# PY32F032xx register map
Vendor: Puya; Series: PY32F0; File version: 1.0.0
CPU: CM0+ r0p1, little endian, no MPU, no FPU, 4 interrupt priority bits
Registers are 32-bit, read-write, reset 0x0 unless marked. A register's access mark holds for its fields unless they carry their own. Offsets are from the block's base; [hi:lo] are bit positions; {n}, {i} and the like mark numbered series; 'fields as' and 'values as' point back to an identical list.

## COMP
Base 0x40010200
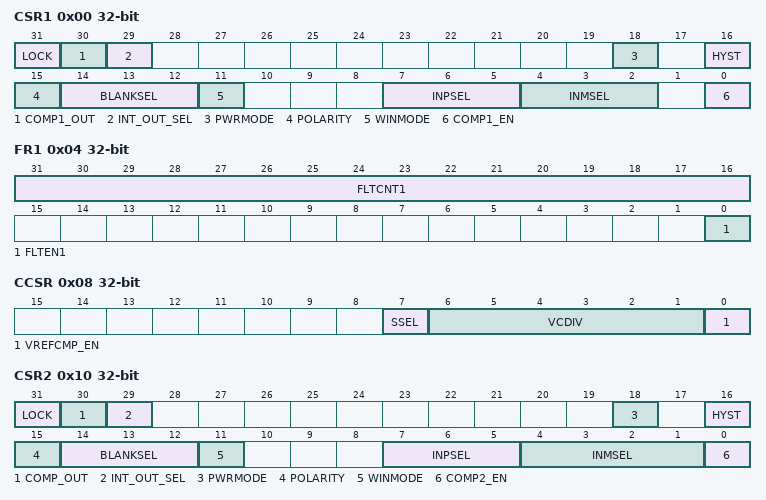
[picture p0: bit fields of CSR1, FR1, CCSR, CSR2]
0x00 CSR1
  [31] LOCK — COMP1_CSR registerlock
  [30] COMP1_OUT ro — COMP1 output status
  [29] INT_OUT_SEL — COMP1 output to TIM/EXTI selection
  [18] PWRMODE — COMP1 power mode selection
  [16] HYST — COMP1 hysteresis function enable control
  [15] POLARITY — COMP1 output polarity selection
  [14:12] BLANKSEL — Comparator 1 blanking signal selection
  [11] WINMODE — COMP1 window mode enable
  [7:5] INPSEL — COMP1 positive input select
  [4:2] INMSEL — COMP1 negative input select
  [0] COMP1_EN — COMP1 enable bit
0x04 FR1
  [31:16] FLTCNT1 — Comparator 1 sampling filter counter
  [0] FLTEN1 — Comparator 1 digital filter configuration
0x08 CCSR
  [7] SSEL
  [6:1] VCDIV
    1=0; 2=1; 4=2; 8=3; 16=4; 32=5
  [0] VREFCMP_EN — VREFCMP voltage divider enable signal
0x10 CSR2
  [31] LOCK — COMP2_CSR register lock
  [30] COMP_OUT ro — COMP2 output status
  [29] INT_OUT_SEL — COMP2 output to TIM/EXTI selection
  [18] PWRMODE — COMP2 power mode selection
  [16] HYST — COMP1 hysteresis function enable control
  [15] POLARITY — COMP2 output polarity selection
  [14:12] BLANKSEL — Comparator 2 blanking signal selection
  [11] WINMODE
  [7:5] INPSEL — COMP2 positive input select
  [4:1] INMSEL — COMP2 negative input select
  [0] COMP2_EN — COMP2 enable bit
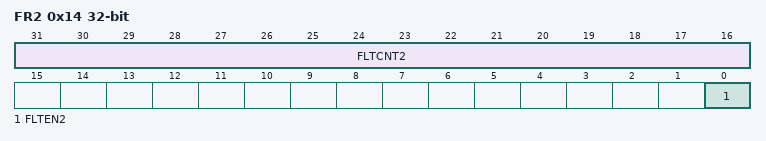
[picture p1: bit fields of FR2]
0x14 FR2
  [31:16] FLTCNT2 — Comparator 2 sampling filter counter
  [0] FLTEN2 — Comparator 2 digital filtering configuration

## CRC — CRC calculation unit
Base 0x40023000
0x00 DR — Data register
0x04 IDR — Independent Data register
  [7:0] IDR
0x08 CR wo — Control register
  [0] RESET

## DBGMCU — Debug support
Base 0x40015800
0x00 DBG_IDCODE
  [31:0] DBG_ID ro
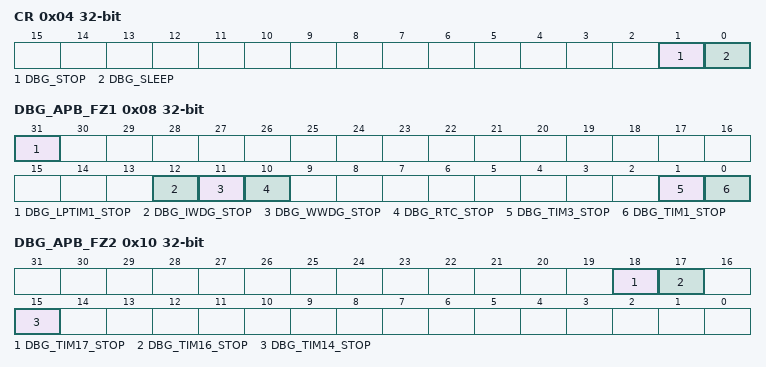
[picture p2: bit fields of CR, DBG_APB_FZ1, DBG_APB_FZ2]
0x04 CR — Debug MCU Configuration Register
  [1] DBG_STOP, [0] DBG_SLEEP
0x08 DBG_APB_FZ1
  [31] DBG_LPTIM1_STOP, [12] DBG_IWDG_STOP, [11] DBG_WWDG_STOP, [10] DBG_RTC_STOP, [1] DBG_TIM3_STOP, [0] DBG_TIM1_STOP
0x10 DBG_APB_FZ2
  [18] DBG_TIM17_STOP, [17] DBG_TIM16_STOP, [15] DBG_TIM14_STOP

## DMA — Direct memory access
Base 0x40020000
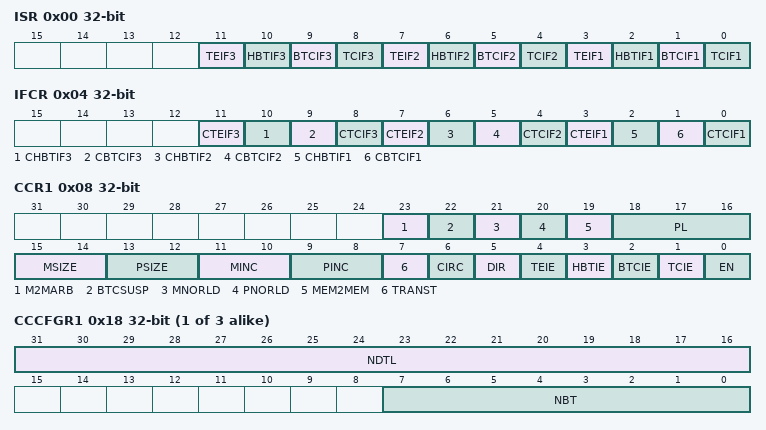
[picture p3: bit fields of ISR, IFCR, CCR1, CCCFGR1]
0x00 ISR — DMA interrupt status register(DMA_ISR)
  [11] TEIF3 ro — Transfer Error Flag for Channel 3
  [10] HBTIF3 ro — Half Block Transfer Complete Flag for Channel 3
  [9] BTCIF3 ro — Block Transfer Complete Flag for Channel 3
  [8] TCIF3 ro — Transfer Complete Flag for Channel 3
  [7] TEIF2 ro — Transfer Error Flag for Channel 2
  [6] HBTIF2 ro — Half Block Transfer Complete Flag for Channel 2
  [5] BTCIF2 ro — Block Transfer Complete Flag for Channel 2
  [4] TCIF2 ro — Transfer Complete Flag for Channel 2
  [3] TEIF1 ro — Transfer Error Flag for Channel 1
  [2] HBTIF1 ro — Half Block Transfer Complete Flag for Channel 1
  [1] BTCIF1 ro — Block Transfer Complete Flag for Channel 1
  [0] TCIF1 ro — Transfer Complete Flag for Channel 1
0x04 IFCR — DMA interrupt flag clear register(DMA_IFCR)
  [11] CTEIF3 — Transfer Error Flag Clear for Channel 3
  [10] CHBTIF3 — Half Block Transfer Complete Flag Clear for Channel 3
  [9] CBTCIF3 — Block Transfer Complete Flag Clear for Channel 3
  [8] CTCIF3 — Transfer Complete Flag Clear for Channel 3
  [7] CTEIF2 — Transfer Error Flag Clear for Channel 2
  [6] CHBTIF2 — Half Block Transfer Complete Flag Clear for Channel 2
  [5] CBTCIF2 — Block Transfer Complete Flag Clear for Channel 2
  [4] CTCIF2 — Transfer Complete Flag Clear for Channel 2
  [3] CTEIF1 — Transfer Error Flag Clear for Channel 1
  [2] CHBTIF1 — Half Block Transfer Complete Flag Clear for Channel 1
  [1] CBTCIF1 — Block Transfer Complete Flag Clear for Channel 1
  [0] CTCIF1 — Transfer Complete Flag Clear for Channel 1
0x08 CCR1 — DMA channel configuration register(DMA_CCR)
  [23] M2MARB — Memory-to-memory Mode Arbitration
  [22] BTCSUSP — Suspend in Block Transfer Complete Interrupt
  [21] MNORLD — Memory No Reload
  [20] PNORLD — Peripheral No Reload
  [19] MEM2MEM — Memory-to-memory Mode
  [18:16] PL — Priority Level
  [15:14] MSIZE — Memory Size
  [13:12] PSIZE — Peripheral Size
  [11:10] MINC — Memory Increment Mode
  [9:8] PINC — Peripheral Increment Mode
  [7] TRANST — Transfer Type
  [6] CIRC — Circular Mode
  [5] DIR — Data Transfer Direction
  [4] TEIE — Transfer Error Interrupt Enable
  [3] HBTIE — Half Block Transfer Complete Interrupt Enable
  [2] BTCIE — Block Transfer Complete Interrupt Enable
  [1] TCIE — Transfer Complete Interrupt Enable
  [0] EN — Channel Enable
0x0C CNDTR1 — DMA channel 1 number of dataregister
  [15:0] NDT — Number of Data to Transfer
0x10 CPAR1 — DMA channel 1 peripheral addressregister
  [31:0] PA — Peripheral Address
{0x0+0x14*i} CMAR{i} (i=1..3) — DMA channel {i} memory addressregister
  [31:0] MA — Memory Address
{0x4+0x14*i} CCCFGR{i} (i=1..3)
  [31:16] NDTL — Number of Data to Transfer Last Loop
  [7:0] NBT — Number of Block to Loop Transfer
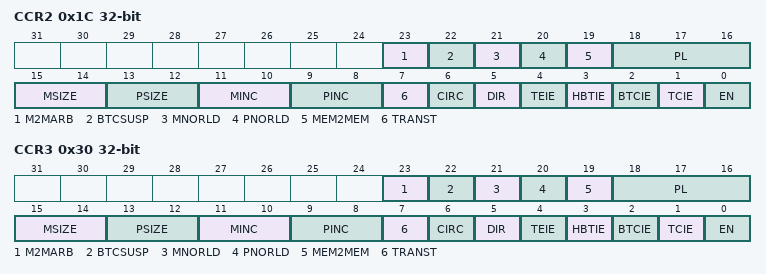
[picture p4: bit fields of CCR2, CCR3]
0x1C CCR2 — DMA channel configuration register(DMA_CCR)
  fields as CCR1
0x20 CNDTR2 — DMA channel 2 number of dataregister
  [15:0] NDT — Number of Data to Transfer
0x24 CPAR2 — DMA channel 2 peripheral addressregister
  [31:0] PA — Peripheral Address
0x30 CCR3 — DMA channel configuration register(DMA_CCR)
  fields as CCR1
0x34 CNDTR3 — DMA channel 3 number of dataregister
  [15:0] NDT — Number of Data to Transfer
0x38 CPAR3 — DMA channel 3 peripheral addressregister
  [31:0] PA — Peripheral Address
